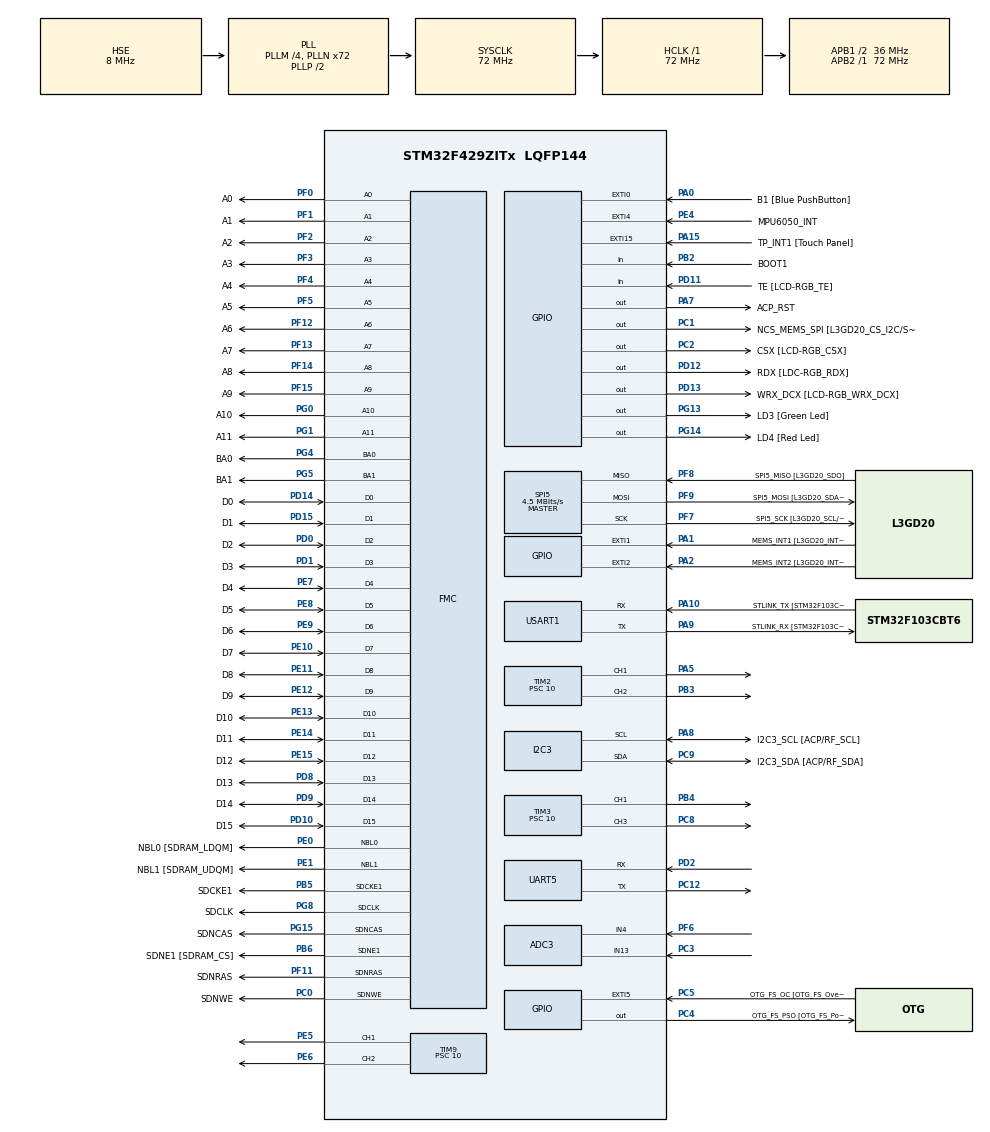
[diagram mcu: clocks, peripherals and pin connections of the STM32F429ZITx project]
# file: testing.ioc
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ADC3.Channel-2\#ChannelRegularConversion=ADC_CHANNEL_4
ADC3.NbrOfConversionFlag=1
ADC3.Rank-2\#ChannelRegularConversion=1
ADC3.SamplingTime-2\#ChannelRegularConversion=ADC_SAMPLETIME_3CYCLES
Dma.Request0=UART5_RX
Dma.UART5_RX.0.Direction=DMA_PERIPH_TO_MEMORY
Dma.UART5_RX.0.FIFOMode=DMA_FIFOMODE_DISABLE
Dma.UART5_RX.0.Instance=DMA1_Stream0
Dma.UART5_RX.0.MemDataAlignment=DMA_MDATAALIGN_BYTE
Dma.UART5_RX.0.MemInc=DMA_MINC_ENABLE
Dma.UART5_RX.0.Mode=DMA_NORMAL
Dma.UART5_RX.0.PeriphDataAlignment=DMA_PDATAALIGN_BYTE
Dma.UART5_RX.0.PeriphInc=DMA_PINC_DISABLE
Dma.UART5_RX.0.Priority=DMA_PRIORITY_LOW
I2C3.I2C_Mode=I2C_Standard
Mcu.Family=STM32F4
Mcu.Name=STM32F429ZITx
Mcu.Package=LQFP144
NVIC.DMA1_Stream0_IRQn=true\:0\:0\:false\:false\:true\:false\:true\:true
NVIC.EXTI4_IRQn=true\:15\:0\:true\:false\:true\:true\:true\:true
NVIC.PriorityGroup=NVIC_PRIORITYGROUP_4
NVIC.TIM6_DAC_IRQn=true\:14\:0\:true\:false\:true\:false\:true\:true
NVIC.TimeBase=TIM6_DAC_IRQn
NVIC.TimeBaseIP=TIM6
PA0/WKUP.GPIO_Label=B1 [Blue PushButton]
PA0/WKUP.GPIO_ModeDefaultEXTI=GPIO_MODE_EVT_RISING
PA0/WKUP.GPIO_PuPd=GPIO_NOPULL
PA0/WKUP.Signal=GPXTI0
PA1.GPIO_Label=MEMS_INT1 [L3GD20_INT1]
PA1.GPIO_ModeDefaultEXTI=GPIO_MODE_EVT_RISING
PA1.GPIO_PuPd=GPIO_NOPULL
PA1.Signal=GPXTI1
PA10.GPIO_Label=STLINK_TX [STM32F103CBT6_PA2]
PA10.Mode=Asynchronous
PA10.Signal=USART1_RX
PA11.GPIO_Label=R4
PA11.GPIO_Mode=GPIO_MODE_AF_PP
PA11.GPIO_PuPd=GPIO_NOPULL
PA11.GPIO_Speed=GPIO_SPEED_FREQ_LOW
PA11.Signal=LTDC_R4
PA12.GPIO_Label=R5
PA12.GPIO_Mode=GPIO_MODE_AF_PP
PA12.GPIO_PuPd=GPIO_NOPULL
PA12.GPIO_Speed=GPIO_SPEED_FREQ_LOW
PA12.Signal=LTDC_R5
PA13.GPIO_Label=SWDIO
PA13.Mode=Serial_Wire
PA13.Signal=SYS_JTMS-SWDIO
PA14.GPIO_Label=SWCLK
PA14.Mode=Serial_Wire
PA14.Signal=SYS_JTCK-SWCLK
PA15.GPIO_Label=TP_INT1 [Touch Panel]
PA15.GPIO_ModeDefaultEXTI=GPIO_MODE_EVT_RISING
PA15.GPIO_PuPd=GPIO_NOPULL
PA15.Signal=GPXTI15
PA2.GPIO_Label=MEMS_INT2 [L3GD20_INT2]
PA2.GPIO_ModeDefaultEXTI=GPIO_MODE_EVT_RISING
PA2.GPIO_PuPd=GPIO_NOPULL
PA2.Signal=GPXTI2
PA3.GPIO_Label=B5
PA3.GPIO_Mode=GPIO_MODE_AF_PP
PA3.GPIO_PuPd=GPIO_NOPULL
PA3.GPIO_Speed=GPIO_SPEED_FREQ_LOW
PA3.Signal=LTDC_B5
PA4.GPIO_Label=VSYNC
PA4.GPIO_Mode=GPIO_MODE_AF_PP
PA4.GPIO_PuPd=GPIO_NOPULL
PA4.GPIO_Speed=GPIO_SPEED_FREQ_LOW
PA4.Signal=LTDC_VSYNC
PA5.Signal=S_TIM2_CH1_ETR
PA6.GPIO_Label=G2
PA6.GPIO_Mode=GPIO_MODE_AF_PP
PA6.GPIO_PuPd=GPIO_NOPULL
PA6.GPIO_Speed=GPIO_SPEED_FREQ_LOW
PA6.Signal=LTDC_G2
PA7.GPIO_Label=ACP_RST
PA7.GPIO_Mode=GPIO_MODE_OUTPUT_PP
PA7.GPIO_PuPd=GPIO_NOPULL
PA7.GPIO_Speed=GPIO_SPEED_FREQ_LOW
PA7.Signal=GPIO_Output
PA8.GPIO_Label=I2C3_SCL [ACP/RF_SCL]
PA8.GPIO_Mode=GPIO_MODE_AF_OD
PA8.GPIO_Pu=GPIO_PULLUP
PA8.GPIO_PuPd=GPIO_NOPULL
PA8.GPIO_Speed=GPIO_SPEED_FREQ_LOW
PA8.Mode=I2C
PA8.Signal=I2C3_SCL
PA9.GPIO_Label=STLINK_RX [STM32F103CBT6_PA3]
PA9.Mode=Asynchronous
PA9.Signal=USART1_TX
PB0.GPIO_Label=R3
PB0.GPIO_Mode=GPIO_MODE_AF_PP
PB0.GPIO_PuPd=GPIO_NOPULL
PB0.GPIO_Speed=GPIO_SPEED_FREQ_LOW
PB0.Signal=LTDC_R3
PB1.GPIO_Label=R6
PB1.GPIO_Mode=GPIO_MODE_AF_PP
PB1.GPIO_PuPd=GPIO_NOPULL
PB1.GPIO_Speed=GPIO_SPEED_FREQ_LOW
PB1.Signal=LTDC_R6
PB10.GPIO_Label=G4
PB10.GPIO_Mode=GPIO_MODE_AF_PP
PB10.GPIO_PuPd=GPIO_NOPULL
PB10.GPIO_Speed=GPIO_SPEED_FREQ_LOW
PB10.Signal=LTDC_G4
PB11.GPIO_Label=G5
PB11.GPIO_Mode=GPIO_MODE_AF_PP
PB11.GPIO_PuPd=GPIO_NOPULL
PB11.GPIO_Speed=GPIO_SPEED_FREQ_LOW
PB11.Signal=LTDC_G5
PB12.GPIO_Label=OTG_HS_ID
PB12.GPIO_Mode=GPIO_MODE_AF_PP
PB12.GPIO_PuPd=GPIO_NOPULL
PB12.GPIO_Speed=GPIO_SPEED_FREQ_LOW
PB12.Signal=USB_OTG_HS_ID
PB13.GPIO_Label=VBUS_HS
PB13.GPIO_Mode=GPIO_MODE_INPUT
PB13.GPIO_PuPd=GPIO_NOPULL
PB13.Signal=USB_OTG_HS_VBUS
PB14.GPIO_Label=OTG_HS_DM
PB14.GPIO_Mode=GPIO_MODE_AF_PP
PB14.GPIO_PuPd=GPIO_NOPULL
PB14.GPIO_Speed=GPIO_SPEED_FREQ_LOW
PB14.Signal=USB_OTG_HS_DM
PB15.GPIO_Label=OTG_HS_DP
PB15.GPIO_Mode=GPIO_MODE_AF_PP
PB15.GPIO_PuPd=GPIO_NOPULL
PB15.GPIO_Speed=GPIO_SPEED_FREQ_LOW
PB15.Signal=USB_OTG_HS_DP
PB2/BOOT1.GPIO_Label=BOOT1
PB2/BOOT1.GPIO_Mode=GPIO_MODE_INPUT
PB2/BOOT1.GPIO_PuPd=GPIO_NOPULL
PB2/BOOT1.Signal=GPIO_Input
PB3.Signal=S_TIM2_CH2
PB4.Signal=S_TIM3_CH1
PB5.GPIO_Label=SDCKE1
PB5.GPIO_Mode=GPIO_MODE_AF_PP
PB5.GPIO_PuPd=GPIO_NOPULL
PB5.GPIO_Speed=GPIO_SPEED_FREQ_VERY_HIGH
PB5.Mode=SdramChipSelect2_1
PB5.Signal=FMC_SDCKE1
PB6.GPIO_Label=SDNE1 [SDRAM_CS]
PB6.GPIO_Mode=GPIO_MODE_AF_PP
PB6.GPIO_PuPd=GPIO_NOPULL
PB6.GPIO_Speed=GPIO_SPEED_FREQ_VERY_HIGH
PB6.Mode=SdramChipSelect2_1
PB6.Signal=FMC_SDNE1
PB8.GPIO_Label=B6
PB8.GPIO_Mode=GPIO_MODE_AF_PP
PB8.GPIO_PuPd=GPIO_NOPULL
PB8.GPIO_Speed=GPIO_SPEED_FREQ_LOW
PB8.Signal=LTDC_B6
PB9.GPIO_Label=B7
PB9.GPIO_Mode=GPIO_MODE_AF_PP
PB9.GPIO_PuPd=GPIO_NOPULL
PB9.GPIO_Speed=GPIO_SPEED_FREQ_LOW
PB9.Signal=LTDC_B7
PC0.GPIO_Label=SDNWE
PC0.GPIO_Mode=GPIO_MODE_AF_PP
PC0.GPIO_PuPd=GPIO_NOPULL
PC0.GPIO_Speed=GPIO_SPEED_FREQ_VERY_HIGH
PC0.Signal=FMC_SDNWE
PC1.GPIO_Label=NCS_MEMS_SPI [L3GD20_CS_I2C/SPI]
PC1.GPIO_Mode=GPIO_MODE_OUTPUT_PP
PC1.GPIO_PuPd=GPIO_NOPULL
PC1.GPIO_Speed=GPIO_SPEED_FREQ_LOW
PC1.Signal=GPIO_Output
PC10.GPIO_Label=R2
PC10.GPIO_Mode=GPIO_MODE_AF_PP
PC10.GPIO_PuPd=GPIO_NOPULL
PC10.GPIO_Speed=GPIO_SPEED_FREQ_LOW
PC10.Signal=LTDC_R2
PC12.Mode=Asynchronous
PC12.Signal=UART5_TX
PC14/OSC32_IN.GPIO_Label=PC14-OSC32_IN
PC14/OSC32_IN.Signal=RCC_OSC32_IN
PC15/OSC32_OUT.GPIO_Label=PC15-OSC32_OUT
PC15/OSC32_OUT.Signal=RCC_OSC32_OUT
PC2.GPIO_Label=CSX [LCD-RGB_CSX]
PC2.GPIO_Mode=GPIO_MODE_OUTPUT_PP
PC2.GPIO_PuPd=GPIO_NOPULL
PC2.GPIO_Speed=GPIO_SPEED_FREQ_LOW
PC2.Signal=GPIO_Output
PC3.Signal=ADCx_IN13
PC4.GPIO_Label=OTG_FS_PSO [OTG_FS_PowerSwitchOn]
PC4.GPIO_Mode=GPIO_MODE_OUTPUT_PP
PC4.GPIO_PuPd=GPIO_NOPULL
PC4.GPIO_Speed=GPIO_SPEED_FREQ_LOW
PC4.Signal=GPIO_Output
PC5.GPIO_Label=OTG_FS_OC [OTG_FS_OverCurrent]
PC5.GPIO_ModeDefaultEXTI=GPIO_MODE_EVT_RISING
PC5.Signal=GPXTI5
PC6.GPIO_Label=HSYNC
PC6.GPIO_Mode=GPIO_MODE_AF_PP
PC6.GPIO_PuPd=GPIO_NOPULL
PC6.GPIO_Speed=GPIO_SPEED_FREQ_LOW
PC6.Signal=LTDC_HSYNC
PC7.GPIO_Label=G6
PC7.GPIO_Mode=GPIO_MODE_AF_PP
PC7.GPIO_PuPd=GPIO_NOPULL
PC7.GPIO_Speed=GPIO_SPEED_FREQ_LOW
PC7.Signal=LTDC_G6
PC8.Signal=S_TIM3_CH3
PC9.GPIO_Label=I2C3_SDA [ACP/RF_SDA]
PC9.GPIO_Mode=GPIO_MODE_AF_OD
PC9.GPIO_Pu=GPIO_PULLUP
PC9.GPIO_PuPd=GPIO_NOPULL
PC9.GPIO_Speed=GPIO_SPEED_FREQ_LOW
PC9.Mode=I2C
PC9.Signal=I2C3_SDA
PD0.GPIO_Label=D2
PD0.GPIO_Mode=GPIO_MODE_AF_PP
PD0.GPIO_PuPd=GPIO_NOPULL
PD0.GPIO_Speed=GPIO_SPEED_FREQ_VERY_HIGH
PD0.Signal=FMC_D2_DA2
PD1.GPIO_Label=D3
PD1.GPIO_Mode=GPIO_MODE_AF_PP
PD1.GPIO_PuPd=GPIO_NOPULL
PD1.GPIO_Speed=GPIO_SPEED_FREQ_VERY_HIGH
PD1.Signal=FMC_D3_DA3
PD10.GPIO_Label=D15
PD10.GPIO_Mode=GPIO_MODE_AF_PP
PD10.GPIO_PuPd=GPIO_NOPULL
PD10.GPIO_Speed=GPIO_SPEED_FREQ_VERY_HIGH
PD10.Signal=FMC_D15_DA15
PD11.GPIO_Label=TE [LCD-RGB_TE]
PD11.GPIO_Mode=GPIO_MODE_INPUT
PD11.GPIO_PuPd=GPIO_NOPULL
PD11.Signal=GPIO_Input
PD12.GPIO_Label=RDX [LDC-RGB_RDX]
PD12.GPIO_Mode=GPIO_MODE_OUTPUT_PP
PD12.GPIO_PuPd=GPIO_NOPULL
PD12.GPIO_Speed=GPIO_SPEED_FREQ_LOW
PD12.Signal=GPIO_Output
PD13.GPIO_Label=WRX_DCX [LCD-RGB_WRX_DCX]
PD13.GPIO_Mode=GPIO_MODE_OUTPUT_PP
PD13.GPIO_PuPd=GPIO_NOPULL
PD13.GPIO_Speed=GPIO_SPEED_FREQ_LOW
PD13.Signal=GPIO_Output
PD14.GPIO_Label=D0
PD14.GPIO_Mode=GPIO_MODE_AF_PP
PD14.GPIO_PuPd=GPIO_NOPULL
PD14.GPIO_Speed=GPIO_SPEED_FREQ_VERY_HIGH
PD14.Signal=FMC_D0_DA0
PD15.GPIO_Label=D1
PD15.GPIO_Mode=GPIO_MODE_AF_PP
PD15.GPIO_PuPd=GPIO_NOPULL
PD15.GPIO_Speed=GPIO_SPEED_FREQ_VERY_HIGH
PD15.Signal=FMC_D1_DA1
PD2.Mode=Asynchronous
PD2.Signal=UART5_RX
PD3.GPIO_Label=G7
PD3.GPIO_Mode=GPIO_MODE_AF_PP
PD3.GPIO_PuPd=GPIO_NOPULL
PD3.GPIO_Speed=GPIO_SPEED_FREQ_LOW
PD3.Signal=LTDC_G7
PD6.GPIO_Label=B2
PD6.GPIO_Mode=GPIO_MODE_AF_PP
PD6.GPIO_PuPd=GPIO_NOPULL
PD6.GPIO_Speed=GPIO_SPEED_FREQ_LOW
PD6.Signal=LTDC_B2
PD8.GPIO_Label=D13
PD8.GPIO_Mode=GPIO_MODE_AF_PP
PD8.GPIO_PuPd=GPIO_NOPULL
PD8.GPIO_Speed=GPIO_SPEED_FREQ_VERY_HIGH
PD8.Signal=FMC_D13_DA13
PD9.GPIO_Label=D14
PD9.GPIO_Mode=GPIO_MODE_AF_PP
PD9.GPIO_PuPd=GPIO_NOPULL
PD9.GPIO_Speed=GPIO_SPEED_FREQ_VERY_HIGH
PD9.Signal=FMC_D14_DA14
PE0.GPIO_Label=NBL0 [SDRAM_LDQM]
PE0.GPIO_Mode=GPIO_MODE_AF_PP
PE0.GPIO_PuPd=GPIO_NOPULL
PE0.GPIO_Speed=GPIO_SPEED_FREQ_VERY_HIGH
PE0.Signal=FMC_NBL0
PE1.GPIO_Label=NBL1 [SDRAM_UDQM]
PE1.GPIO_Mode=GPIO_MODE_AF_PP
PE1.GPIO_PuPd=GPIO_NOPULL
PE1.GPIO_Speed=GPIO_SPEED_FREQ_VERY_HIGH
PE1.Signal=FMC_NBL1
PE10.GPIO_Label=D7
PE10.GPIO_Mode=GPIO_MODE_AF_PP
PE10.GPIO_PuPd=GPIO_NOPULL
PE10.GPIO_Speed=GPIO_SPEED_FREQ_VERY_HIGH
PE10.Signal=FMC_D7_DA7
PE11.GPIO_Label=D8
PE11.GPIO_Mode=GPIO_MODE_AF_PP
PE11.GPIO_PuPd=GPIO_NOPULL
PE11.GPIO_Speed=GPIO_SPEED_FREQ_VERY_HIGH
PE11.Signal=FMC_D8_DA8
PE12.GPIO_Label=D9
PE12.GPIO_Mode=GPIO_MODE_AF_PP
PE12.GPIO_PuPd=GPIO_NOPULL
PE12.GPIO_Speed=GPIO_SPEED_FREQ_VERY_HIGH
PE12.Signal=FMC_D9_DA9
PE13.GPIO_Label=D10
PE13.GPIO_Mode=GPIO_MODE_AF_PP
PE13.GPIO_PuPd=GPIO_NOPULL
PE13.GPIO_Speed=GPIO_SPEED_FREQ_VERY_HIGH
PE13.Signal=FMC_D10_DA10
PE14.GPIO_Label=D11
PE14.GPIO_Mode=GPIO_MODE_AF_PP
PE14.GPIO_PuPd=GPIO_NOPULL
PE14.GPIO_Speed=GPIO_SPEED_FREQ_VERY_HIGH
PE14.Signal=FMC_D11_DA11
PE15.GPIO_Label=D12
PE15.GPIO_Mode=GPIO_MODE_AF_PP
PE15.GPIO_PuPd=GPIO_NOPULL
PE15.GPIO_Speed=GPIO_SPEED_FREQ_VERY_HIGH
PE15.Signal=FMC_D12_DA12
PE4.GPIO_Label=MPU6050_INT
PE4.GPIO_ModeDefaultEXTI=GPIO_MODE_IT_RISING
PE4.Signal=GPXTI4
PE5.Signal=S_TIM9_CH1
PE6.Signal=S_TIM9_CH2
PE7.GPIO_Label=D4
PE7.GPIO_Mode=GPIO_MODE_AF_PP
PE7.GPIO_PuPd=GPIO_NOPULL
PE7.GPIO_Speed=GPIO_SPEED_FREQ_VERY_HIGH
PE7.Signal=FMC_D4_DA4
PE8.GPIO_Label=D5
PE8.GPIO_Mode=GPIO_MODE_AF_PP
PE8.GPIO_PuPd=GPIO_NOPULL
PE8.GPIO_Speed=GPIO_SPEED_FREQ_VERY_HIGH
PE8.Signal=FMC_D5_DA5
PE9.GPIO_Label=D6
PE9.GPIO_Mode=GPIO_MODE_AF_PP
PE9.GPIO_PuPd=GPIO_NOPULL
PE9.GPIO_Speed=GPIO_SPEED_FREQ_VERY_HIGH
PE9.Signal=FMC_D6_DA6
PF0.GPIO_Label=A0
PF0.GPIO_Mode=GPIO_MODE_AF_PP
PF0.GPIO_PuPd=GPIO_NOPULL
PF0.GPIO_Speed=GPIO_SPEED_FREQ_VERY_HIGH
PF0.Signal=FMC_A0
PF1.GPIO_Label=A1
PF1.GPIO_Mode=GPIO_MODE_AF_PP
PF1.GPIO_PuPd=GPIO_NOPULL
PF1.GPIO_Speed=GPIO_SPEED_FREQ_VERY_HIGH
PF1.Signal=FMC_A1
PF10.GPIO_Label=ENABLE [LCD-RGB_ENABLE]
PF10.GPIO_Mode=GPIO_MODE_AF_PP
PF10.GPIO_PuPd=GPIO_NOPULL
PF10.GPIO_Speed=GPIO_SPEED_FREQ_LOW
PF10.Signal=LTDC_DE
PF11.GPIO_Label=SDNRAS
PF11.GPIO_Mode=GPIO_MODE_AF_PP
PF11.GPIO_PuPd=GPIO_NOPULL
PF11.GPIO_Speed=GPIO_SPEED_FREQ_VERY_HIGH
PF11.Signal=FMC_SDNRAS
PF12.GPIO_Label=A6
PF12.GPIO_Mode=GPIO_MODE_AF_PP
PF12.GPIO_PuPd=GPIO_NOPULL
PF12.GPIO_Speed=GPIO_SPEED_FREQ_VERY_HIGH
PF12.Signal=FMC_A6
PF13.GPIO_Label=A7
PF13.GPIO_Mode=GPIO_MODE_AF_PP
PF13.GPIO_PuPd=GPIO_NOPULL
PF13.GPIO_Speed=GPIO_SPEED_FREQ_VERY_HIGH
PF13.Signal=FMC_A7
PF14.GPIO_Label=A8
PF14.GPIO_Mode=GPIO_MODE_AF_PP
PF14.GPIO_PuPd=GPIO_NOPULL
PF14.GPIO_Speed=GPIO_SPEED_FREQ_VERY_HIGH
PF14.Signal=FMC_A8
PF15.GPIO_Label=A9
PF15.GPIO_Mode=GPIO_MODE_AF_PP
PF15.GPIO_PuPd=GPIO_NOPULL
PF15.GPIO_Speed=GPIO_SPEED_FREQ_VERY_HIGH
PF15.Signal=FMC_A9
PF2.GPIO_Label=A2
PF2.GPIO_Mode=GPIO_MODE_AF_PP
PF2.GPIO_PuPd=GPIO_NOPULL
PF2.GPIO_Speed=GPIO_SPEED_FREQ_VERY_HIGH
PF2.Signal=FMC_A2
PF3.GPIO_Label=A3
PF3.GPIO_Mode=GPIO_MODE_AF_PP
PF3.GPIO_PuPd=GPIO_NOPULL
PF3.GPIO_Speed=GPIO_SPEED_FREQ_VERY_HIGH
PF3.Signal=FMC_A3
PF4.GPIO_Label=A4
PF4.GPIO_Mode=GPIO_MODE_AF_PP
PF4.GPIO_PuPd=GPIO_NOPULL
PF4.GPIO_Speed=GPIO_SPEED_FREQ_VERY_HIGH
PF4.Signal=FMC_A4
PF5.GPIO_Label=A5
PF5.GPIO_Mode=GPIO_MODE_AF_PP
PF5.GPIO_PuPd=GPIO_NOPULL
PF5.GPIO_Speed=GPIO_SPEED_FREQ_VERY_HIGH
PF5.Signal=FMC_A5
PF6.Mode=IN4
PF6.Signal=ADC3_IN4
PF7.GPIO_Label=SPI5_SCK [L3GD20_SCL/SPC]
PF7.GPIO_Mode=GPIO_MODE_AF_PP
PF7.GPIO_PuPd=GPIO_NOPULL
PF7.GPIO_Speed=GPIO_SPEED_FREQ_LOW
PF7.Mode=Full_Duplex_Master
PF7.Signal=SPI5_SCK
PF8.GPIO_Label=SPI5_MISO [L3GD20_SDO]
PF8.GPIO_Mode=GPIO_MODE_AF_PP
PF8.GPIO_PuPd=GPIO_NOPULL
PF8.GPIO_Speed=GPIO_SPEED_FREQ_LOW
PF8.Mode=Full_Duplex_Master
PF8.Signal=SPI5_MISO
PF9.GPIO_Label=SPI5_MOSI [L3GD20_SDA/SDI/SDO]
PF9.GPIO_Mode=GPIO_MODE_AF_PP
PF9.GPIO_PuPd=GPIO_NOPULL
PF9.GPIO_Speed=GPIO_SPEED_FREQ_LOW
PF9.Mode=Full_Duplex_Master
PF9.Signal=SPI5_MOSI
PG0.GPIO_Label=A10
PG0.GPIO_Mode=GPIO_MODE_AF_PP
PG0.GPIO_PuPd=GPIO_NOPULL
PG0.GPIO_Speed=GPIO_SPEED_FREQ_VERY_HIGH
PG0.Signal=FMC_A10
PG1.GPIO_Label=A11
PG1.GPIO_Mode=GPIO_MODE_AF_PP
PG1.GPIO_PuPd=GPIO_NOPULL
PG1.GPIO_Speed=GPIO_SPEED_FREQ_VERY_HIGH
PG1.Signal=FMC_A11
PG10.GPIO_Label=G3
PG10.GPIO_Mode=GPIO_MODE_AF_PP
PG10.GPIO_PuPd=GPIO_NOPULL
PG10.GPIO_Speed=GPIO_SPEED_FREQ_LOW
PG10.Signal=LTDC_G3
PG11.GPIO_Label=B3
PG11.GPIO_Mode=GPIO_MODE_AF_PP
PG11.GPIO_PuPd=GPIO_NOPULL
PG11.GPIO_Speed=GPIO_SPEED_FREQ_LOW
PG11.Signal=LTDC_B3
PG12.GPIO_Label=B4
PG12.GPIO_Mode=GPIO_MODE_AF_PP
PG12.GPIO_PuPd=GPIO_NOPULL
PG12.GPIO_Speed=GPIO_SPEED_FREQ_LOW
PG12.Signal=LTDC_B4
PG13.GPIO_Label=LD3 [Green Led]
PG13.GPIO_Mode=GPIO_MODE_OUTPUT_PP
PG13.GPIO_PuPd=GPIO_NOPULL
PG13.GPIO_Speed=GPIO_SPEED_FREQ_LOW
PG13.Signal=GPIO_Output
PG14.GPIO_Label=LD4 [Red Led]
PG14.GPIO_Mode=GPIO_MODE_OUTPUT_PP
PG14.GPIO_PuPd=GPIO_NOPULL
PG14.GPIO_Speed=GPIO_SPEED_FREQ_LOW
PG14.Signal=GPIO_Output
PG15.GPIO_Label=SDNCAS
PG15.GPIO_Mode=GPIO_MODE_AF_PP
PG15.GPIO_PuPd=GPIO_NOPULL
PG15.GPIO_Speed=GPIO_SPEED_FREQ_VERY_HIGH
PG15.Signal=FMC_SDNCAS
PG4.GPIO_Label=BA0
PG4.GPIO_Mode=GPIO_MODE_AF_PP
PG4.GPIO_PuPd=GPIO_NOPULL
PG4.GPIO_Speed=GPIO_SPEED_FREQ_VERY_HIGH
PG4.Signal=FMC_A14_BA0
PG5.GPIO_Label=BA1
PG5.GPIO_Mode=GPIO_MODE_AF_PP
PG5.GPIO_PuPd=GPIO_NOPULL
PG5.GPIO_Speed=GPIO_SPEED_FREQ_VERY_HIGH
PG5.Signal=FMC_A15_BA1
PG6.GPIO_Label=R7
PG6.GPIO_Mode=GPIO_MODE_AF_PP
PG6.GPIO_PuPd=GPIO_NOPULL
PG6.GPIO_Speed=GPIO_SPEED_FREQ_LOW
PG6.Signal=LTDC_R7
PG7.GPIO_Label=DOTCLK [LCT-RGB_DOTCLK]
PG7.GPIO_Mode=GPIO_MODE_AF_PP
PG7.GPIO_PuPd=GPIO_NOPULL
PG7.GPIO_Speed=GPIO_SPEED_FREQ_LOW
PG7.Signal=LTDC_CLK
PG8.GPIO_Label=SDCLK
PG8.GPIO_Mode=GPIO_MODE_AF_PP
PG8.GPIO_PuPd=GPIO_NOPULL
PG8.GPIO_Speed=GPIO_SPEED_FREQ_VERY_HIGH
PG8.Signal=FMC_SDCLK
PH0/OSC_IN.GPIO_Label=PH0-OSC_IN
PH0/OSC_IN.Mode=HSE-External-Oscillator
PH0/OSC_IN.Signal=RCC_OSC_IN
PH1/OSC_OUT.GPIO_Label=PH1-OSC_OUT
PH1/OSC_OUT.Mode=HSE-External-Oscillator
PH1/OSC_OUT.Signal=RCC_OSC_OUT
ProjectManager.HeapSize=0x200
ProjectManager.StackSize=0x400
ProjectManager.TargetToolchain=STM32CubeIDE
RCC.48MHZClocksFreq_Value=48000000
RCC.AHBFreq_Value=72000000
RCC.APB1CLKDivider=RCC_HCLK_DIV2
RCC.APB1Freq_Value=36000000
RCC.APB1TimFreq_Value=72000000
RCC.APB2Freq_Value=72000000
RCC.APB2TimFreq_Value=72000000
RCC.CortexFreq_Value=72000000
RCC.HCLKFreq_Value=72000000
RCC.HSE_VALUE=8000000
RCC.HSI_VALUE=16000000
RCC.LSE_VALUE=32768
RCC.PLLM=4
RCC.PLLN=72
RCC.PLLQ=3
RCC.PLLSAIN=50
RCC.PLLSourceVirtual=RCC_PLLSOURCE_HSE
RCC.SYSCLKFreq_VALUE=72000000
RCC.SYSCLKSource=RCC_SYSCLKSOURCE_PLLCLK
RCC.VCOOutputFreq_Value=144000000
SH.ADCx_IN13.0=ADC3_IN13,IN13
SH.FMC_A0.0=FMC_A0,12b-sda1
SH.FMC_A1.0=FMC_A1,12b-sda1
SH.FMC_A10.0=FMC_A10,12b-sda1
SH.FMC_A11.0=FMC_A11,12b-sda1
SH.FMC_A14_BA0.0=FMC_BA0,FourSdramBanks1
SH.FMC_A15_BA1.0=FMC_BA1,FourSdramBanks1
SH.FMC_A2.0=FMC_A2,12b-sda1
SH.FMC_A3.0=FMC_A3,12b-sda1
SH.FMC_A4.0=FMC_A4,12b-sda1
SH.FMC_A5.0=FMC_A5,12b-sda1
SH.FMC_A6.0=FMC_A6,12b-sda1
SH.FMC_A7.0=FMC_A7,12b-sda1
SH.FMC_A8.0=FMC_A8,12b-sda1
SH.FMC_A9.0=FMC_A9,12b-sda1
SH.FMC_D0_DA0.0=FMC_D0,sd-16b-d1
SH.FMC_D10_DA10.0=FMC_D10,sd-16b-d1
SH.FMC_D11_DA11.0=FMC_D11,sd-16b-d1
SH.FMC_D12_DA12.0=FMC_D12,sd-16b-d1
SH.FMC_D13_DA13.0=FMC_D13,sd-16b-d1
SH.FMC_D14_DA14.0=FMC_D14,sd-16b-d1
SH.FMC_D15_DA15.0=FMC_D15,sd-16b-d1
SH.FMC_D1_DA1.0=FMC_D1,sd-16b-d1
SH.FMC_D2_DA2.0=FMC_D2,sd-16b-d1
SH.FMC_D3_DA3.0=FMC_D3,sd-16b-d1
SH.FMC_D4_DA4.0=FMC_D4,sd-16b-d1
SH.FMC_D5_DA5.0=FMC_D5,sd-16b-d1
SH.FMC_D6_DA6.0=FMC_D6,sd-16b-d1
SH.FMC_D7_DA7.0=FMC_D7,sd-16b-d1
SH.FMC_D8_DA8.0=FMC_D8,sd-16b-d1
SH.FMC_D9_DA9.0=FMC_D9,sd-16b-d1
SH.FMC_NBL0.0=FMC_NBL0,Sd2ByteEnable1
SH.FMC_NBL1.0=FMC_NBL1,Sd2ByteEnable1
SH.FMC_SDCLK.0=FMC_SDCLK,12b-sda1
SH.FMC_SDNCAS.0=FMC_SDNCAS,12b-sda1
SH.FMC_SDNRAS.0=FMC_SDNRAS,12b-sda1
SH.FMC_SDNWE.0=FMC_SDNWE,12b-sda1
SH.S_TIM2_CH1_ETR.0=TIM2_CH1,PWM Generation1 CH1
SH.S_TIM2_CH2.0=TIM2_CH2,PWM Generation2 CH2
SH.S_TIM3_CH1.0=TIM3_CH1,PWM Generation1 CH1
SH.S_TIM3_CH3.0=TIM3_CH3,PWM Generation3 CH3
SH.S_TIM9_CH1.0=TIM9_CH1,PWM Generation1 CH1
SH.S_TIM9_CH2.0=TIM9_CH2,PWM Generation2 CH2
SPI5.BaudRatePrescaler=SPI_BAUDRATEPRESCALER_16
SPI5.CalculateBaudRate=4.5 MBits/s
SPI5.Direction=SPI_DIRECTION_2LINES
SPI5.Mode=SPI_MODE_MASTER
SPI5.VirtualType=VM_MASTER
TIM2.Channel-PWM\ Generation1\ CH1=TIM_CHANNEL_1
TIM2.Channel-PWM\ Generation2\ CH2=TIM_CHANNEL_2
TIM2.Period=65535
TIM2.Prescaler=10
TIM3.Channel-PWM\ Generation1\ CH1=TIM_CHANNEL_1
TIM3.Channel-PWM\ Generation3\ CH3=TIM_CHANNEL_3
TIM3.Prescaler=10
TIM9.Channel-PWM\ Generation1\ CH1=TIM_CHANNEL_1
TIM9.Channel-PWM\ Generation2\ CH2=TIM_CHANNEL_2
TIM9.Prescaler=10
UART5.VirtualMode=Asynchronous
USART1.VirtualMode=VM_ASYNC
VP_CRC_VS_CRC.Mode=CRC_Activate
VP_SYS_VS_tim6.Mode=TIM6
VP_TIM10_VS_ClockSourceINT.Mode=Enable_Timer
VP_TIM1_VS_ClockSourceINT.Mode=Internal
board=STM32F429I-DISC1

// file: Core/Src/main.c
/* USER CODE BEGIN Header */
/**
  ******************************************************************************
  * @file           : main.c
  * @brief          : Main program body
  ******************************************************************************
  * @attention
  *
  * Copyright (c) 2024 STMicroelectronics.
  * All rights reserved.
  *
  * This software is licensed under terms that can be found in the LICENSE file
  * in the root directory of this software component.
  * If no LICENSE file comes with this software, it is provided AS-IS.
  *
  ******************************************************************************
  */
/* USER CODE END Header */
#include "main.h"
#include "adc.h"
#include "crc.h"
#include "dma.h"
#include "i2c.h"
#include "spi.h"
#include "tim.h"
#include "usart.h"
#include "gpio.h"
#include "fmc.h"

/* USER CODE BEGIN Includes */
#include "printf.h"
#include <stdlib.h>
#include <stdio.h>
#include "math.h"
#include "MPU6050.h"
//#include "MPU6050I2C.h"

#include "inverse_kinematics.h"
/* USER CODE END Includes */

/* USER CODE BEGIN PTD */

#define MOTOR_MIN_DC 5.24
#define MOTOR_MAX_DC 24.76

#define CMD_MAX_LEN 10
#define RX_BUFF_LEN CMD_MAX_LEN
#define CMD_BUFF_LEN CMD_MAX_LEN*2
#define NUM_OF_MOTORS 6
#define ACC_THRESHOLD 80
#define GYRO_THRESHOLD 5

#define ACC_I2C_THRESHOLD 0.8
#define GYRO_I2C_THRESHOLD 5

#define FLEX_LOW_THRESHOLD 5
#define FLEX_HIGH_THRESHOLD 5

#define ALPHA 0
#define BETA 1
#define ZETA 2
#define GAMMA 3

#define BASE_MOTOR_NUM GAMMA
#define SHOULDER_MOTOR_NUM ALPHA
#define ELBOW_MOTOR_NUM BETA
#define WRIST_MOTOR_NUM ZETA
#define GRIPPER_MOTOR_NUM 5

#define END_EFF_DEFAULT_POSITION {0, 0, LINK_1_LEN+LINK_1_LEN+LINK_1_LEN}
#define ARM_DEFAULT_ANGLES {M_PI/2, M_PI/2,M_PI/2,M_PI/2}

#define MAX_POSITION_INC 0.05

#define ORIENTATAION_NEUTRAL 0
#define ORIENTATAION_X_PLUS 1
#define ORIENTATAION_X_NEG 2
#define ORIENTATAION_Y_PLUS 3
#define ORIENTATAION_Y_NEG 4
#define ORIENTATAION_Z_PLUS 5
#define ORIENTATAION_Z_NEG 6

#define ARM_STATIONARY 0
#define ARM_MOVING 0

typedef enum
{
  ACCELERATION,
  ANGULAR_SPEED
} ACC_DataType;

typedef struct
{
	volatile uint32_t *ccr;
	volatile double cur_DC;
	double min_duty_cycle;
	double max_duty_cycle;
	double offset;
}MotorTypedef;

typedef struct
{
	volatile uint8_t *buff;
	volatile uint16_t curr_pos;
	uint16_t read_pos;
	volatile uint8_t buffer_full;
	volatile uint8_t buff_init;
	volatile uint8_t catch_up;

}CommandBuffTypedef;

typedef struct
{
	float accel[3];
	float gyro[3];
	float flex[2];
}SensorsStateDefType;

typedef struct
{
	uint8_t orientation;
	uint8_t arm_moving;
	double eef_curr_pos[3];

}SystemStateDefType;

/* USER CODE END PTD */

/* USER CODE BEGIN PV */

uint8_t rx_buff[RX_BUFF_LEN];

volatile uint8_t command_buffer[CMD_BUFF_LEN];

CommandBuffTypedef cmd_buff =  {command_buffer, 0, 0, 0, 1, 1};

volatile double motor_angles[NUM_OF_MOTORS];

volatile uint8_t EXTI4_FLAG = 0;

/* USER CODE END PV */

void SystemClock_Config(void);
/* USER CODE BEGIN PFP */
void move_arm(MotorTypedef *motors, SystemStateDefType *system_state);
void run_trajectory(double *trajectory, uint8_t steps, double time);
void putchar_(char c);
void set_duty_cycle(MotorTypedef *motor, double duty_cycle);
HAL_StatusTypeDef process_cmds(CommandBuffTypedef *Command_Buff, MotorTypedef *motors, SystemStateDefType *system_state);
void process_motor_command(uint8_t *command,  MotorTypedef *motors);
void process_accelerometer_command(uint8_t *command);
int get_hand_orientation(volatile float acceleration[], volatile float ang_speed[], volatile float flex_read[]);
void set_end_effector_position(MotorTypedef motors[], double position[]);

/* USER CODE END PFP */

/* USER CODE BEGIN 0 */

//void move_arm(MotorTypedef *motors, SystemStateDefType *system_state){
//
//	if (system_state->orientation!= ORIENTATAION_NEUTRAL){
//		double eef_final_pos[3] = {system_state->eef_curr_pos[0], system_state->eef_curr_pos[1], system_state->eef_curr_pos[2]};
//		switch (system_state->orientation){
//			case ORIENTATAION_Y_PLUS:
//				eef_final_pos[1] = system_state->eef_curr_pos[1] + MAX_POSITION_INC;
//				break;
//			case ORIENTATAION_Y_NEG:
//				eef_final_pos[1] = system_state->eef_curr_pos[1] - MAX_POSITION_INC;
//				break;
//			case ORIENTATAION_X_PLUS:
//				eef_final_pos[0] = system_state->eef_curr_pos[0] + MAX_POSITION_INC;
//				break;
//			case ORIENTATAION_X_NEG:
//				eef_final_pos[0] = system_state->eef_curr_pos[0] - MAX_POSITION_INC;
//				break;
//			case ORIENTATAION_Z_PLUS:
//				eef_final_pos[2] = system_state->eef_curr_pos[2] + MAX_POSITION_INC;
//				break;
//			case ORIENTATAION_Z_NEG:
//				eef_final_pos[2] = system_state->eef_curr_pos[2] - MAX_POSITION_INC;
//				break;
//			default:
//				break;
//		}
//		printf_("Position [%0.2f][%0.2f][%0.2f] \n", eef_final_pos[0],eef_final_pos[1],eef_final_pos[2]);
//
//		double alpha_f, beta_f, zeta_f, gamma_f;
//		calculate_angles(eef_final_pos, &alpha_f, &beta_f, &zeta_f, &gamma_f);
//
//
//		if(check_angle_validty(alpha_f, beta_f, zeta_f, gamma_f) == 0){
//			uint8_t steps = 10;
//			double time_period = 0.01;
//			uint32_t delay = time_period*1000/steps;
//			double angle_trajectory[4][steps+1];
//			calculate_trajectory(system_state->eef_curr_pos, eef_final_pos, 0, 0, time_period, steps, (double*)angle_trajectory);
//			//Run the Trajectory
//			for(uint8_t i = 0; i<=steps; i++ ){
//				printf_("alpha: %0f, beta: %f, zeta: %f, gamma: %f\n", angle_trajectory[ALPHA][i], angle_trajectory[BETA][i],angle_trajectory[ZETA][i], angle_trajectory[GAMMA][i]);
//				set_duty_cycle(&motors[BASE_MOTOR_NUM],angle_trajectory[BASE_MOTOR_NUM][i] + BASE_MOTOR_OFFSET_RAD);
//				set_duty_cycle(&motors[SHOULDER_MOTOR_NUM],angle_trajectory[SHOULDER_MOTOR_NUM][i] +SHOULDER_MOTOR_OFFSET_RAD);
//				set_duty_cycle(&motors[ELBOW_MOTOR_NUM],angle_trajectory[ELBOW_MOTOR_NUM][i]+ELBOW_MOTOR_OFFSET_RAD);
//				set_duty_cycle(&motors[WRIST_MOTOR_NUM],angle_trajectory[WRIST_MOTOR_NUM][i]+WRIST_MOTOR_OFFSET_RAD);
//				HAL_Delay(delay);
//			}
//			system_state->eef_curr_pos[0] = eef_final_pos[0];
//			system_state->eef_curr_pos[1] = eef_final_pos[1];
//			system_state->eef_curr_pos[2] = eef_final_pos[2];
//		}
//		else{
//			printf_("Position [%0.2f][%0.2f][%0.2f] not reachable \n", eef_final_pos[0],eef_final_pos[1],eef_final_pos[2]);
//		}
//	}
//}

void move_arm(MotorTypedef *motors, SystemStateDefType *system_state){

	if (system_state->orientation!= ORIENTATAION_NEUTRAL){

		double eef_final_pos[3] = {system_state->eef_curr_pos[0], system_state->eef_curr_pos[1], system_state->eef_curr_pos[2]};

		uint8_t axis = 0;
		int8_t direction = 0;

//		double eef_final_pos[3];
		switch (system_state->orientation){
			case ORIENTATAION_Y_PLUS:
//				eef_final_pos[1] = system_state->eef_curr_pos[1] + 5;
				axis = 1;
				direction = +1;
				break;
			case ORIENTATAION_Y_NEG:
//				eef_final_pos[1] = system_state->eef_curr_pos[1] - 5;
				axis = 1;
				direction = -1;
				break;
			case ORIENTATAION_X_PLUS:
//				eef_final_pos[0] = system_state->eef_curr_pos[0] + 5;
				axis = 0;
				direction = +1;
				break;
			case ORIENTATAION_X_NEG:
//				eef_final_pos[0] = system_state->eef_curr_pos[0] - 5;
				axis = 0;
				direction = -1;
				break;
			case ORIENTATAION_Z_PLUS:
//				eef_final_pos[2] = system_state->eef_curr_pos[2] + 5;
				axis = 2;
				direction = +1;
				break;
			case ORIENTATAION_Z_NEG:
//				eef_final_pos[2] = system_state->eef_curr_pos[2] - 5;
				axis = 2;
				direction = -1;
				break;
			default:
				break;

		}

		printf_("Orientation:%d\n",system_state->orientation );

		double alpha_f, beta_f, zeta_f, gamma_f;
		double increment = 0.01;
		for (uint8_t i = 1;i<=50; i++){
			eef_final_pos[axis] += ((double)direction)*increment;
//			printf_("dir - %d, dir*inc - %f\n",direction, ((double)direction)*increment );
			calculate_angles(eef_final_pos, &alpha_f, &beta_f, &zeta_f, &gamma_f);
			if(check_angle_validty(alpha_f, beta_f, zeta_f, gamma_f) == 0){
				system_state->eef_curr_pos[axis] = eef_final_pos[axis];
//				printf_("Position [%0.2f][%0.2f][%0.2f]\n", system_state->eef_curr_pos[0],system_state->eef_curr_pos[1],system_state->eef_curr_pos[2]);
				set_duty_cycle(&motors[BASE_MOTOR_NUM],gamma_f + BASE_MOTOR_OFFSET_RAD);
				set_duty_cycle(&motors[SHOULDER_MOTOR_NUM],alpha_f + SHOULDER_MOTOR_OFFSET_RAD);
				set_duty_cycle(&motors[ELBOW_MOTOR_NUM],beta_f + ELBOW_MOTOR_OFFSET_RAD);
				set_duty_cycle(&motors[WRIST_MOTOR_NUM],zeta_f + WRIST_MOTOR_OFFSET_RAD);
				HAL_Delay(5);
			}
			else{
//				printf_("Position [%0.2f][%0.2f][%0.2f] not reachable \n", eef_final_pos[0],eef_final_pos[1],eef_final_pos[2]);
				break;
			}
		}
//		printf_("Position [%0.2f][%0.2f][%0.2f]\n", system_state->eef_curr_pos[0],system_state->eef_curr_pos[1],system_state->eef_curr_pos[2]);
	}
}

void set_duty_cycle(MotorTypedef *motor, double angle){
	// Angle(Radians)
	double duty_cycle = (double)(motor->min_duty_cycle + ((angle)*(motor->max_duty_cycle - motor->min_duty_cycle)/M_PI));
	*(motor->ccr) = (uint32_t)((duty_cycle * (double)(0xFFFF))/100);
	motor->cur_DC = duty_cycle;
}

//int set_motor_angle(MotorTypedef *motor, double angle){
//	// Angle(Radians)
//	if ((angle<(M_PI+motor->offset))&&(angle>(0+motor->offset))){
//		double duty_cycle = (double)(motor->min_duty_cycle + ((angle)*(motor->max_duty_cycle - motor->min_duty_cycle)/M_PI));
//		*(motor->ccr) = (uint32_t)((duty_cycle * (double)(0xFFFF))/100);
//		motor->cur_DC = duty_cycle;
//		return 0;
//	}
//	return 1;
//}

void process_motor_command(uint8_t *command, MotorTypedef *motors){
	uint8_t motor = command[1] - '0'; // convert the second letter to an integer
	char *ptr;

	if (motor >= 0 && motor < NUM_OF_MOTORS){
	  float angle = strtof((char*)command + 3, &ptr); // convert the rest of the string to a double

	  if (angle >= 0 && angle <= 190){

		set_duty_cycle(&motors[motor], (angle*M_PI)/180);
		printf_("Motor %d set to %.2f degrees.\n", motor, angle); // print the result

	  }

	  else{
		printf_("Invalid angle.\n"); // print an error message
	  }
	}

	else{
	  printf_("Invalid motor number.\n"); // print an error message
	}

}

int get_hand_orientation(volatile float acceleration[], volatile float ang_speed[], volatile float flex_read[]){

	if ((abs(ang_speed[0])>GYRO_THRESHOLD) || (abs(ang_speed[0])>GYRO_THRESHOLD) ||(abs(ang_speed[0])>GYRO_THRESHOLD)){
		printf_("Hand Shaky");
		return ORIENTATAION_NEUTRAL;
	}
	else{

		if(acceleration[0]>ACC_THRESHOLD){
			printf_("Backward\n");
			return ORIENTATAION_Y_NEG;
		}

		else if(acceleration[0]<-ACC_THRESHOLD){
			printf_("Forward\n");
			return ORIENTATAION_Y_PLUS;
		}

		else if(acceleration[1]<-ACC_THRESHOLD){
			printf_("Left\n");
			return ORIENTATAION_X_PLUS;
		}

		else if(acceleration[1]>ACC_THRESHOLD){
			printf_("Right\n");
			return ORIENTATAION_X_NEG;
		}

		else if(acceleration[2]<-ACC_THRESHOLD){
			printf_("Down\n");
			return ORIENTATAION_Z_NEG;
		}

		else if(acceleration[2]>ACC_THRESHOLD){
			printf_("Neutral\n");
			return ORIENTATAION_NEUTRAL;
		}
		else{
			printf_("Invalid Orientation\n");
			return ORIENTATAION_NEUTRAL;
		}

	}
}

void process_accelerometer_command(uint8_t *command){

	uint8_t type = command[2]-'0';

	float data[3];

	if(type == ACCELERATION){
		MPU6050_Read_Accel(&data[0], &data[1], &data[2]);
	}
	else if (type == ANGULAR_SPEED){
		MPU6050_Read_Gyro(&data[0], &data[1], &data[2]);

	}

	else{
		printf_("Accelerometer Command Error");
	}

}

void save_cmd(UART_HandleTypeDef *huart){

	uint8_t buff_init_copy = cmd_buff.buff_init;

	for(uint8_t i = 0; i<RX_BUFF_LEN; i++){

		if(cmd_buff.buffer_full==1){
				printf_("Buffer Full\n");
				return;
			}

		else{
			if(cmd_buff.curr_pos == cmd_buff.read_pos){

				if(!(cmd_buff.buff_init || cmd_buff.catch_up)){
					cmd_buff.buffer_full = 1;
					printf_("Buffer Full\n");
					return;
				}
			}
		}

		cmd_buff.buff_init = 0;
		cmd_buff.buff[cmd_buff.curr_pos] = rx_buff[i];

		uint8_t end_of_message = 0;

		if(cmd_buff.buff[cmd_buff.curr_pos] == '$'){
			if(i != RX_BUFF_LEN -1)
			{
				HAL_UART_DMAStop(&huart5);
				cmd_buff.curr_pos = cmd_buff.curr_pos -(i);
				if (buff_init_copy == 1){
					cmd_buff.buff_init = 1;
				}

				printf_("Invalid Command\n");
				break;
			}

			end_of_message = 1;
		}

		if(cmd_buff.curr_pos==CMD_BUFF_LEN-1){
			cmd_buff.curr_pos=0;
		}
		else{
			cmd_buff.curr_pos+=1;
		}

		if((i == RX_BUFF_LEN -1) && (end_of_message == 0) ){
			HAL_UART_DMAStop(&huart5);
			cmd_buff.curr_pos = cmd_buff.curr_pos -(i+1);
			if (buff_init_copy == 1){
				cmd_buff.buff_init = 1;
			}

			printf_("Invalid Command\n");
			break;
		}

		if(end_of_message == 1){
//			HAL_UART_Transmit(huart, rx_buff, i+1, HAL_MAX_DELAY);
			cmd_buff.catch_up = 0;
			break;
		}
	}
}

HAL_StatusTypeDef process_cmds(CommandBuffTypedef *Command_Buff, MotorTypedef *motors, SystemStateDefType *system_state){
	if(Command_Buff->read_pos == Command_Buff->curr_pos){
		if ((cmd_buff.buff_init || cmd_buff.catch_up)){
			return HAL_ERROR;
		}
	}

	while(Command_Buff->catch_up != 1){
		uint8_t cmd[CMD_MAX_LEN];
		uint8_t cmd_len = 0;
		for(uint8_t i = 0; i<CMD_MAX_LEN; i++){
			cmd_len = i+1;
			if (Command_Buff->buff[Command_Buff->read_pos]!='$'){
				cmd[i] = Command_Buff->buff[Command_Buff->read_pos];
				if(Command_Buff->read_pos == CMD_BUFF_LEN-1){
					Command_Buff->read_pos = 0;
				}
				else{
					Command_Buff->read_pos+=1;
				}
			}
			else{
				cmd[i] = '$';
				if(Command_Buff->read_pos == CMD_BUFF_LEN-1){
					Command_Buff->read_pos = 0;
				}
				else{
					Command_Buff->read_pos+=1;
				}
				break;
			}
		}

		if(Command_Buff->read_pos == Command_Buff->curr_pos){
			cmd_buff.catch_up = 1;
		}

		if(Command_Buff->buffer_full == 1){
			Command_Buff->buffer_full = 0;
		}

		uint8_t new_line = '\n';
		HAL_UART_Transmit(&huart5, cmd, cmd_len, HAL_MAX_DELAY);
		HAL_UART_Transmit(&huart5, &new_line, 1, HAL_MAX_DELAY);

		uint8_t a = cmd[0];
		switch (a){
		case 'M':
			process_motor_command(cmd, motors);
			break;

		case 'A':
			process_accelerometer_command(cmd);
			break;

		case 'O':
			system_state->orientation = cmd[2]-'0';
			break;

		default:
			return HAL_ERROR;
		}
	}

	return HAL_OK;

}

void putchar_(char c) {
    // Transmit the string
    if (HAL_UART_Transmit(&huart5, (uint8_t*)&c, 1, HAL_MAX_DELAY)!= HAL_OK)
    {
    	Error_Handler();
    }
}

void HAL_UART_RxCpltCallback(UART_HandleTypeDef *huart){

	save_cmd(huart);
    HAL_UART_Receive_DMA(huart, rx_buff, 10);

}

/* USER CODE END 0 */

int main(void)
{

  /* MCU Configuration--------------------------------------------------------*/

  /* Reset of all peripherals, Initializes the Flash interface and the Systick. */
  HAL_Init();

  /* Configure the system clock */
  SystemClock_Config();

  /* Initialize all configured peripherals */
  MX_GPIO_Init();
  MX_DMA_Init();
  MX_CRC_Init();
  MX_FMC_Init();
  MX_I2C3_Init();
  MX_SPI5_Init();
  MX_TIM1_Init();
  MX_USART1_UART_Init();
  MX_ADC3_Init();
  MX_TIM2_Init();
  MX_TIM3_Init();
  MX_TIM9_Init();
  MX_TIM10_Init();
  MX_UART5_Init();
  /* USER CODE BEGIN 2 */
//  HAL_TIM_PWM_Init(&htim9);

  HAL_UART_Receive_DMA(&huart5, rx_buff, 10);

  HAL_TIM_PWM_Start(&htim2, TIM_CHANNEL_1);
  HAL_TIM_PWM_Start(&htim2, TIM_CHANNEL_2);
  HAL_TIM_PWM_Start(&htim3, TIM_CHANNEL_1);
  HAL_TIM_PWM_Start(&htim3, TIM_CHANNEL_3);
  HAL_TIM_PWM_Start(&htim9, TIM_CHANNEL_1);
  HAL_TIM_PWM_Start(&htim9, TIM_CHANNEL_2);

//  char buf[4];

//  MPU6050_init();
//  MPU6050_Initialization();

  MotorTypedef motors[NUM_OF_MOTORS] = {
  		  {&(htim2.Instance->CCR1), 0.0, MOTOR_MIN_DC, MOTOR_MAX_DC},
  		  {&(htim2.Instance->CCR2), 0.0, MOTOR_MIN_DC, MOTOR_MAX_DC},
  		  {&(htim3.Instance->CCR1), 0.0, MOTOR_MIN_DC, MOTOR_MAX_DC},
  		  {&(htim3.Instance->CCR3), 0.0, MOTOR_MIN_DC, MOTOR_MAX_DC},
  		  {&(htim9.Instance->CCR1), 0.0, MOTOR_MIN_DC, MOTOR_MAX_DC},
  		  {&(htim9.Instance->CCR2), 0.0, MOTOR_MIN_DC, MOTOR_MAX_DC}
  };

  // Setting the arm to default position
  set_duty_cycle(&motors[BASE_MOTOR_NUM], ((90 + BASE_MOTOR_OFFSET)*M_PI)/180);
  set_duty_cycle(&motors[SHOULDER_MOTOR_NUM], ((91 +SHOULDER_MOTOR_OFFSET)*M_PI)/180);
  set_duty_cycle(&motors[ELBOW_MOTOR_NUM], ((99 + ELBOW_MOTOR_OFFSET)*M_PI)/180);
  set_duty_cycle(&motors[WRIST_MOTOR_NUM], ((78 + WRIST_MOTOR_OFFSET)*M_PI)/180);

//  SensorsStateDefType sensors;
  SystemStateDefType system_state;
  system_state.orientation = ORIENTATAION_NEUTRAL;
  system_state.eef_curr_pos[0] = 0.1;
  system_state.eef_curr_pos[1] = 14;
  system_state.eef_curr_pos[2] = 4;
  /* USER CODE END 2 */

  /* Infinite loop */
  /* USER CODE BEGIN WHILE */

  while (1)
  {

    process_cmds(&cmd_buff, motors, &system_state);
    move_arm(motors, &system_state);
//    printf_("Orientation - %d\n",system_state.orientation);

    /* USER CODE END WHILE */

  }
}

void SystemClock_Config(void)
{
  RCC_OscInitTypeDef RCC_OscInitStruct = {0};
  RCC_ClkInitTypeDef RCC_ClkInitStruct = {0};

  /** Configure the main internal regulator output voltage
  */
  __HAL_RCC_PWR_CLK_ENABLE();
  __HAL_PWR_VOLTAGESCALING_CONFIG(PWR_REGULATOR_VOLTAGE_SCALE3);

  /** Initializes the RCC Oscillators according to the specified parameters
  * in the RCC_OscInitTypeDef structure.
  */
  RCC_OscInitStruct.OscillatorType = RCC_OSCILLATORTYPE_HSE;
  RCC_OscInitStruct.HSEState = RCC_HSE_ON;
  RCC_OscInitStruct.PLL.PLLState = RCC_PLL_ON;
  RCC_OscInitStruct.PLL.PLLSource = RCC_PLLSOURCE_HSE;
  RCC_OscInitStruct.PLL.PLLM = 4;
  RCC_OscInitStruct.PLL.PLLN = 72;
  RCC_OscInitStruct.PLL.PLLP = RCC_PLLP_DIV2;
  RCC_OscInitStruct.PLL.PLLQ = 3;
  if (HAL_RCC_OscConfig(&RCC_OscInitStruct) != HAL_OK)
  {
    Error_Handler();
  }

  /** Initializes the CPU, AHB and APB buses clocks
  */
  RCC_ClkInitStruct.ClockType = RCC_CLOCKTYPE_HCLK|RCC_CLOCKTYPE_SYSCLK
                              |RCC_CLOCKTYPE_PCLK1|RCC_CLOCKTYPE_PCLK2;
  RCC_ClkInitStruct.SYSCLKSource = RCC_SYSCLKSOURCE_PLLCLK;
  RCC_ClkInitStruct.AHBCLKDivider = RCC_SYSCLK_DIV1;
  RCC_ClkInitStruct.APB1CLKDivider = RCC_HCLK_DIV2;
  RCC_ClkInitStruct.APB2CLKDivider = RCC_HCLK_DIV1;

  if (HAL_RCC_ClockConfig(&RCC_ClkInitStruct, FLASH_LATENCY_2) != HAL_OK)
  {
    Error_Handler();
  }
}

/* USER CODE BEGIN 4 */

void HAL_GPIO_EXTI_Callback(uint16_t GPIO_Pin)
{
	EXTI4_FLAG = 1;
}

/* USER CODE END 4 */

void HAL_TIM_PeriodElapsedCallback(TIM_HandleTypeDef *htim)
{
  if (htim->Instance == TIM6) {
    HAL_IncTick();
  }
}

void Error_Handler(void)
{
  /* USER CODE BEGIN Error_Handler_Debug */
  /* User can add his own implementation to report the HAL error return state */
  __disable_irq();

//  switch(err_type):
//				  case 0:
//					  printf_("")
//
  while (1)
  {
  }
  /* USER CODE END Error_Handler_Debug */
}
